# STM32N647 register map
File version: 1.0
CPU: CM55 r0p1, little endian, no MPU, FPU, vendor SysTick, 8 interrupt priority bits
Registers are 32-bit, read-write, reset 0x0 unless marked. A register's access mark holds for its fields unless they carry their own. Offsets are from the block's base; [hi:lo] are bit positions; {n}, {i} and the like mark numbered series.

## GPIOA — General-purpose I/Os
Base 0x46020000
Same registers: GPIOA_S 0x56020000
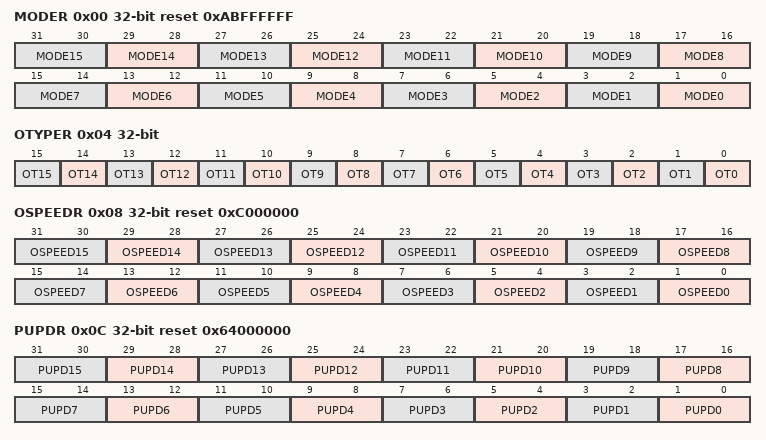
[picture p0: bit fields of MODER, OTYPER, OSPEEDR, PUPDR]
0x00 MODER reset 0xABFFFFFF — GPIO port A mode register
  [2n+1:2n] MODE{n} (n=0..15) — Port x configuration pin {n}
    0=Input mode; 1=Output (General purpose output mode); 2=Alternate function mode; 3=Analog mode
0x04 OTYPER — GPIO port A output type register
  [n] OT{n} (n=0..15) — Port x configuration pin {n}
    0=PushPull (Output push-pull (reset state)); 1=OpenDrain (Output open-drain)
0x08 OSPEEDR reset 0xC000000 — GPIO port A output speed register
  [2n+1:2n] OSPEED{n} (n=0..15) — Port x configuration pin {n}
    0=LowSpeed; 1=MediumSpeed; 2=HighSpeed; 3=VeryHighSpeed
0x0C PUPDR reset 0x64000000 — GPIO port A pull-up/pull-down register
  [2n+1:2n] PUPD{n} (n=0..15) — Port x configuration pin {n}
    0=Floating (No pull-up, pull-down); 1=PullUp; 2=PullDown
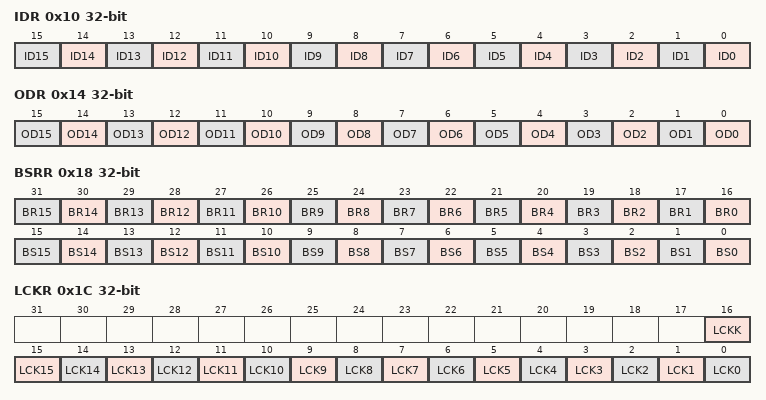
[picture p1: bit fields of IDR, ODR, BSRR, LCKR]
0x10 IDR ro (reset mask 0xFFFF0000) — GPIO port A input data register
  [n] ID{n} (n=0..15) — Port input data pin {n}
    0=Low (Input is logic low); 1=High (Input is logic high)
0x14 ODR — GPIO port A output data register
  [n] OD{n} (n=0..15) — Port output data pin {n}
    0=Low (Set output to logic low); 1=High (Set output to logic high)
0x18 BSRR wo — GPIO port A bit set/reset register
  [n+16] BR{n} (n=0..15) — Port x reset pin {n}
    1=Resets the corresponding ODx bit
  [n] BS{n} (n=0..15) — Port x set pin {n}
    1=Set (Sets the corresponding ODx bit)
0x1C LCKR — GPIO port A configuration lock register
  [16] LCKK — Lock key
    0=NotActive (Port configuration lock key not active); 1=Active (Port configuration lock key active)
  [n] LCK{n} (n=0..15) — Port x lock pin {n}
    0=Unlocked (Port configuration not locked); 1=Locked (Port configuration locked)
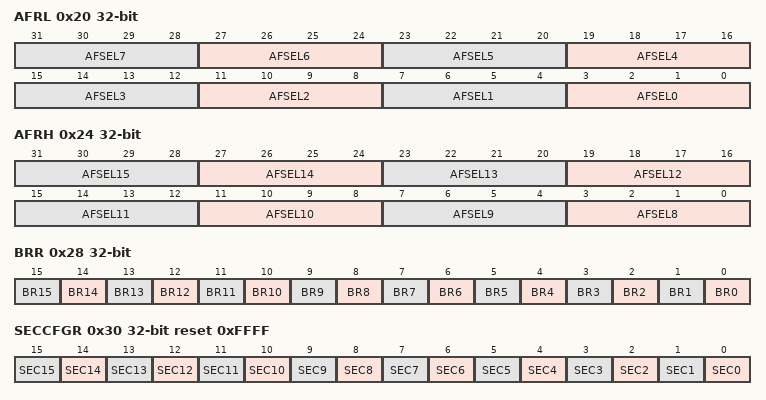
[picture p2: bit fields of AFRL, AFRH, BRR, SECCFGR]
0x20 AFRL — GPIO port A alternate function low register
  [4n+3:4n] AFSEL{n} (n=0..7) — Alternate function selection for port x I/O pin y
    {v}=AF{v} (v=0..15)
0x24 AFRH — GPIO port A alternate function high register
  [4n-29:4n-32] AFSEL{n} (n=8..15) — Alternate function selection for port x I/O pin y
    {v}=AF{v} (v=0..15)
0x28 BRR wo — GPIO port A bit reset register
  [n] BR{n} (n=0..15) — Port x reset pin {n}
    0=No action on the corresponding ODx bit; 1=Reset the ODx bit
0x30 SECCFGR reset 0xFFFF — GPIO port A secure configuration register
  [n] SEC{n} (n=0..15) — I/O pin y of Port x security configuration
    0=NonSecure (The I/O pin is non-secure); 1=Secure (The I/O pin is secure)
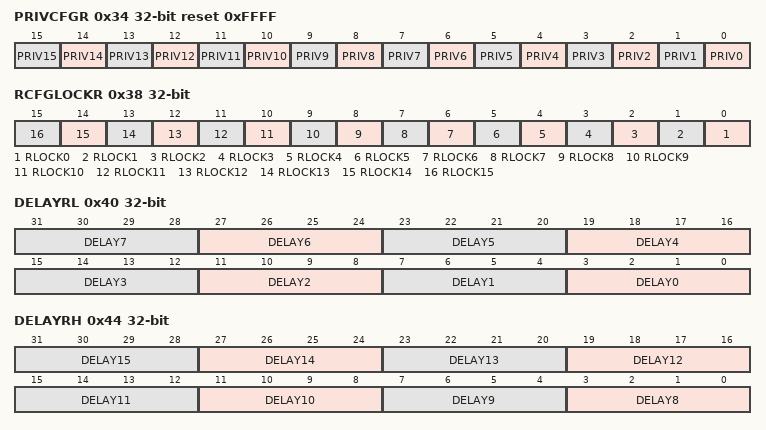
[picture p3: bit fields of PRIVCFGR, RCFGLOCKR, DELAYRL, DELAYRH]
0x34 PRIVCFGR reset 0xFFFF — GPIO port A privileged configuration register
  [n] PRIV{n} (n=0..15) — I/O pin y of Port x privilege configuration
0x38 RCFGLOCKR — GPIO port A resource configuration lock register
  [n] RLOCK{n} (n=0..15) — I/O pin y of port x resource lock
0x40 DELAYRL — GPIO port A delay low register
  [4n+3:4n] DELAY{n} (n=0..7) — Port x IO pin y delay setup
0x44 DELAYRH — GPIO port A delay high register
  [4n-29:4n-32] DELAY{n} (n=8..15) — Port x I/O pin y delay setup
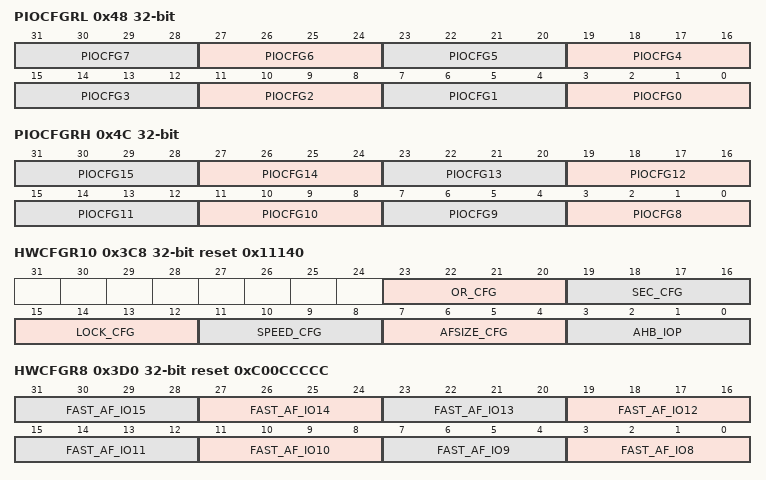
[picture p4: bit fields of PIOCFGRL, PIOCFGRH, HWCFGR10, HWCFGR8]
0x48 PIOCFGRL — GPIO port A PIO control low register
  [4n+3:4n] PIOCFG{n} (n=0..7) — Port x I/O pin y configuration
0x4C PIOCFGRH — GPIO port A PIO control high register
  [4n-29:4n-32] PIOCFG{n} (n=8..15) — Port x I/O pin y configuration
0x3C8 HWCFGR10 ro reset 0x11140 — GPIO port A hardware configuration register 10
  [23:20] OR_CFG — Option register configuration
  [19:16] SEC_CFG — Security activation
  [15:12] LOCK_CFG — Lock mechanism activation
  [11:8] SPEED_CFG — Number of speed lines for each I/O
  [7:4] AFSIZE_CFG — Number of AF available for each I/O (accepted value: 1 to 4)
  [3:0] AHB_IOP — Bus interface selection
0x3CC HWCFGR9 ro reset 0xFFFF — GPIO port A hardware configuration register 9
  [15:0] EN_IO — Presence granularity, each bit indicate the I/O presence
0x3D0 HWCFGR8 ro reset 0xC00CCCCC — GPIO port A hardware configuration register 8
  [4n-29:4n-32] FAST_AF_IO{n} (n=8..15) — Indicate which is the fastest AF for I/Oy (0 to F)
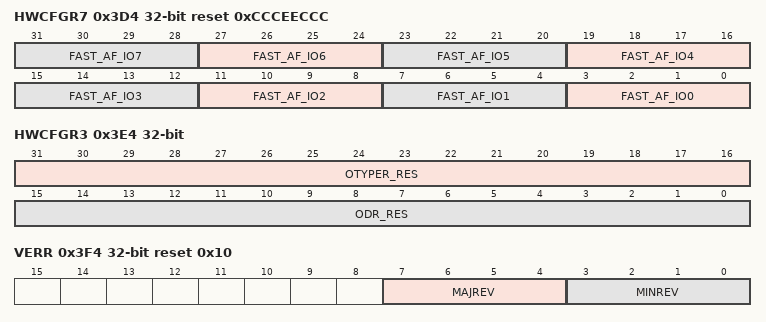
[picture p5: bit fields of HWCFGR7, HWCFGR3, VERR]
0x3D4 HWCFGR7 ro reset 0xCCCEECCC — GPIO port A hardware configuration register 7
  [4n+3:4n] FAST_AF_IO{n} (n=0..7) — Indicate which is the fastest AF for I/Oy (0 to F)
0x3D8 HWCFGR6 ro reset 0xABFFFFFF — GPIO port A hardware configuration register 6
  [31:0] MODER_RES — MODER register reset value
0x3DC HWCFGR5 ro reset 0x64000000 — GPIO port A hardware configuration register 5
  [31:0] PUPDR_RES — Pull-up/pull-down register reset value
0x3E0 HWCFGR4 ro reset 0xC000000 — GPIO port A hardware configuration register 4
  [31:0] OSPEED_RES — OSPEED register reset value
0x3E4 HWCFGR3 ro — GPIO port A hardware configuration register 3
  [31:16] OTYPER_RES — Output type register reset value
  [15:0] ODR_RES — Output data register reset value
0x3E8 HWCFGR2 ro — GPIO port A hardware configuration register 2
  [31:0] AFRL_RES — AF register low reset value
0x3EC HWCFGR1 ro — GPIO port A hardware configuration register 1
  [31:0] AFRH_RES — AF register high reset value
0x3F0 HWCFGR0 ro — GPIO port A hardware configuration register 0
  [15:0] OR_RES — Option register reset value
0x3F4 VERR ro reset 0x10 — GPIO port A version register
  [7:4] MAJREV — GPIO major revision
  [3:0] MINREV — GPIO minor revision
0x3F8 IPIDR ro reset 0xF0004 — GPIO port A identification register
  [31:0] IPID — GPIO identifier
0x3FC SIDR ro reset 0xA3C5DD01 — GPIO port A size identification register
  [31:0] SID — Size of the memory region allocated to GPIO registers
